# f28002x_dev_cfg_regs register map
Vendor: Texas Instruments
Peripheral module from a debugger description file (folder C2000).
Address unit: 16 bits
Registers are 32-bit, read-write, no defined reset value unless marked. A register's access mark holds for its fields unless they carry their own. Offsets are as the file gives them; lines under a group give offsets from that group; [hi:lo] are bit positions; {n}, {i} and the like mark numbered series; 'fields as' and 'values as' point back to an identical list; <NAME> marks a mode.

## DEV_CFG_REGS — DEV CFG Registers
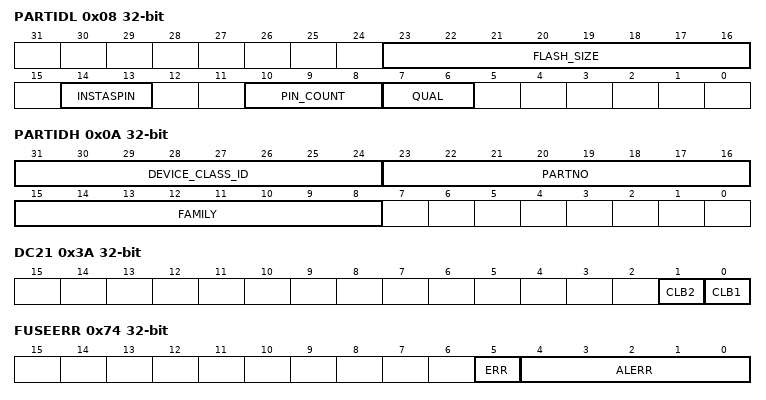
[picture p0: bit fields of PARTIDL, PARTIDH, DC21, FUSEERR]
0x08 PARTIDL — Lower 32-bit of Device PART Identification Number
  [23:16] FLASH_SIZE — Flash size in KB
  [14:13] INSTASPIN — Instaspin feature set
  [10:8] PIN_COUNT — Device Pin Count
  [7:6] QUAL — Qualification Status
0x0A PARTIDH access per field — Upper 32-bit of Device PART Identification Number
  [31:24] DEVICE_CLASS_ID ro
  [23:16] PARTNO rw — Device part number
  [15:8] FAMILY rw — Device family
0x0C REVID ro — Device Revision Number
  [15:0] REVID — Device Revision ID. This is specific to the Device
0x3A DC21 — Device Capability: CLB
  [1] CLB2 — CLB2 Present
  [0] CLB1 — CLB1 Present
0x74 FUSEERR ro — e-Fuse error Status register
  [5] ERR — Efuse Self Test Error Status
  [4:0] ALERR — Efuse Autoload Error Status
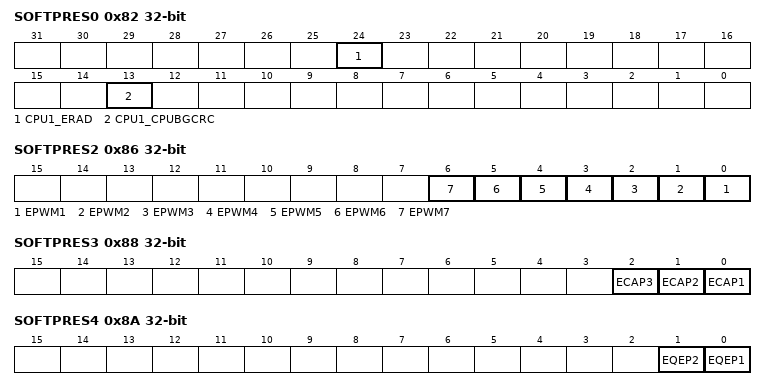
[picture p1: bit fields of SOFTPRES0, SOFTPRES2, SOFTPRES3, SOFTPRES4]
0x82 SOFTPRES0 — Processing Block Software Reset register
  [24] CPU1_ERAD — ERAD Module reset bit
  [13] CPU1_CPUBGCRC — CPUBGCRC Module reset bit
0x86 SOFTPRES2 — Peripheral Software Reset register
  [n-1] EPWM{n} (n=1..7) — EPWM{n} software reset bit
0x88 SOFTPRES3 — Peripheral Software Reset register
  [2] ECAP3 — ECAP3 software reset bit
  [1] ECAP2 — ECAP2 software reset bit
  [0] ECAP1 — ECAP1 software reset bit
0x8A SOFTPRES4 — Peripheral Software Reset register
  [1] EQEP2 — EQEP2 software reset bit
  [0] EQEP1 — EQEP1 software reset bit
0x90 SOFTPRES7 — Peripheral Software Reset register
  [0] SCI_A — SCI_A software reset bit
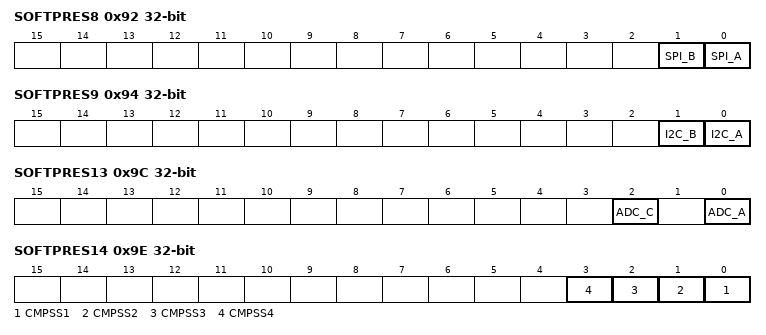
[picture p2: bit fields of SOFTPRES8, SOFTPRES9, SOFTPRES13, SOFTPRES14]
0x92 SOFTPRES8 — Peripheral Software Reset register
  [1] SPI_B — SPI_B software reset bit
  [0] SPI_A — SPI_A software reset bit
0x94 SOFTPRES9 — Peripheral Software Reset register
  [1] I2C_B — I2C_B software reset bit
  [0] I2C_A — I2C_A software reset bit
0x96 SOFTPRES10 — Peripheral Software Reset register
  [0] CAN_A — CAN_A software reset bit
0x9C SOFTPRES13 — Peripheral Software Reset register
  [2] ADC_C — ADC_C software reset bit
  [0] ADC_A — ADC_A software reset bit
0x9E SOFTPRES14 — Peripheral Software Reset register
  [n-1] CMPSS{n} (n=1..4) — CMPSS{n} software reset bit
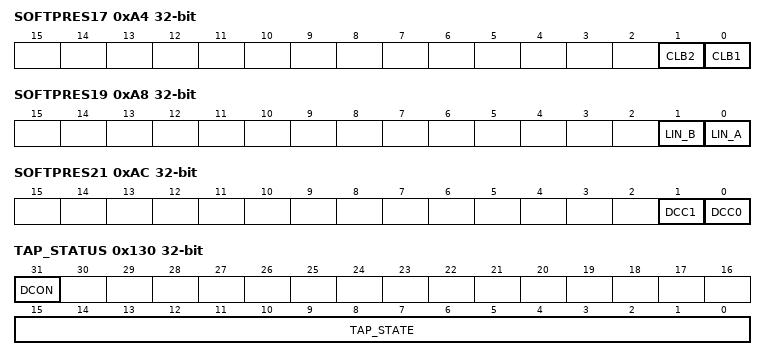
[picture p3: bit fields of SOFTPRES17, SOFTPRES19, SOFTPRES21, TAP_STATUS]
0xA4 SOFTPRES17 — Peripheral Software Reset register
  [1] CLB2 — CLB2 software reset bit
  [0] CLB1 — CLB1 software reset bit
0xA6 SOFTPRES18 access not given — Peripheral Software Reset register
0xA8 SOFTPRES19 — Peripheral Software Reset register
  [1] LIN_B — LIN_B software reset bit
  [0] LIN_A — LIN_A software reset bit
0xAA SOFTPRES20 — Peripheral Software Reset register
  [0] PMBUS_A — PMBUS_A software reset bit
0xAC SOFTPRES21 — Peripheral Software Reset register
  [1] DCC1 — DCC Module reset bit
  [0] DCC0 — DCC Module reset bit
0xB4 SOFTPRES25 — Peripheral Software Reset register
  [0] HIC_A — HIC Slave and Host controller Reset Bit
0x130 TAP_STATUS ro — Status of JTAG State machine and Debugger Connect
  [31] DCON — Debugger Connect Indication
  [15:0] TAP_STATE — Present TAP State
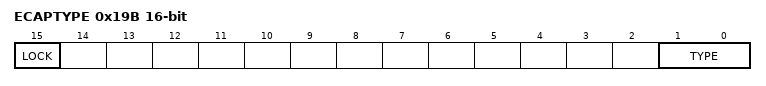
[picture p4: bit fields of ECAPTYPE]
0x19B ECAPTYPE 16-bit — Configures ECAP Type for the device
  [15] LOCK — Lock bit for the register
  [1:0] TYPE — Configure ECAP type
